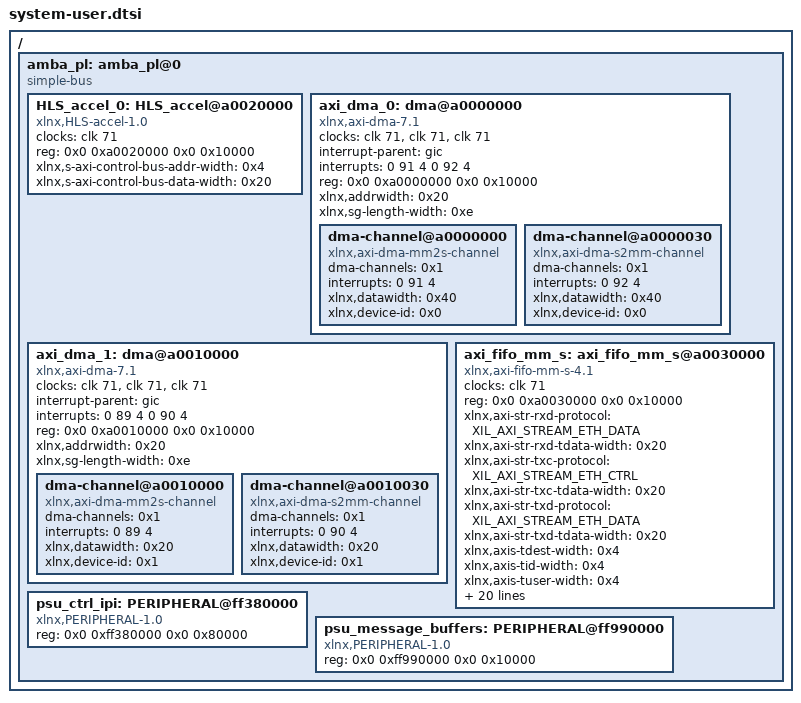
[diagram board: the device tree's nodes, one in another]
/include/ "system-conf.dtsi"
/ {
};
/ {
	amba_pl: amba_pl@0 {
		#address-cells = <2>;
		#size-cells = <2>;
		compatible = "simple-bus";
		ranges ;
		HLS_accel_0: HLS_accel@a0020000 {
			clock-names = "ap_clk";
			clocks = <&clk 71>;
			compatible = "xlnx,HLS-accel-1.0";
			reg = <0x0 0xa0020000 0x0 0x10000>;
			xlnx,s-axi-control-bus-addr-width = <0x4>;
			xlnx,s-axi-control-bus-data-width = <0x20>;
		};
		axi_dma_0: dma@a0000000 {
			#dma-cells = <1>;
			clock-names = "s_axi_lite_aclk", "m_axi_mm2s_aclk", "m_axi_s2mm_aclk";
			clocks = <&clk 71>, <&clk 71>, <&clk 71>;
			compatible = "xlnx,axi-dma-7.1", "xlnx,axi-dma-1.00.a", "generic-uio";
			interrupt-names = "mm2s_introut", "s2mm_introut";
			interrupt-parent = <&gic>;
			interrupts = <0 91 4 0 92 4>;
			reg = <0x0 0xa0000000 0x0 0x10000>;
			xlnx,addrwidth = <0x20>;
			xlnx,sg-length-width = <0xe>;
			dma-channel@a0000000 {
				compatible = "xlnx,axi-dma-mm2s-channel";
				dma-channels = <0x1>;
				interrupts = <0 91 4>;
				xlnx,datawidth = <0x40>;
				xlnx,device-id = <0x0>;
			};
			dma-channel@a0000030 {
				compatible = "xlnx,axi-dma-s2mm-channel";
				dma-channels = <0x1>;
				interrupts = <0 92 4>;
				xlnx,datawidth = <0x40>;
				xlnx,device-id = <0x0>;
			};
		};
		axi_dma_1: dma@a0010000 {
			#dma-cells = <1>;
			clock-names = "s_axi_lite_aclk", "m_axi_mm2s_aclk", "m_axi_s2mm_aclk";
			clocks = <&clk 71>, <&clk 71>, <&clk 71>;
			compatible = "xlnx,axi-dma-7.1", "xlnx,axi-dma-1.00.a", "generic-uio";
			interrupt-names = "mm2s_introut", "s2mm_introut";
			interrupt-parent = <&gic>;
			interrupts = <0 89 4 0 90 4>;
			reg = <0x0 0xa0010000 0x0 0x10000>;
			xlnx,addrwidth = <0x20>;
			xlnx,sg-length-width = <0xe>;
			dma-channel@a0010000 {
				compatible = "xlnx,axi-dma-mm2s-channel";
				dma-channels = <0x1>;
				interrupts = <0 89 4>;
				xlnx,datawidth = <0x20>;
				xlnx,device-id = <0x1>;
			};
			dma-channel@a0010030 {
				compatible = "xlnx,axi-dma-s2mm-channel";
				dma-channels = <0x1>;
				interrupts = <0 90 4>;
				xlnx,datawidth = <0x20>;
				xlnx,device-id = <0x1>;
			};
		};
		axi_fifo_mm_s: axi_fifo_mm_s@a0030000 {
			clock-names = "s_axi_aclk";
			clocks = <&clk 71>;
			compatible = "xlnx,axi-fifo-mm-s-4.1";
			reg = <0x0 0xa0030000 0x0 0x10000>;
			xlnx,axi-str-rxd-protocol = "XIL_AXI_STREAM_ETH_DATA";
			xlnx,axi-str-rxd-tdata-width = <0x20>;
			xlnx,axi-str-txc-protocol = "XIL_AXI_STREAM_ETH_CTRL";
			xlnx,axi-str-txc-tdata-width = <0x20>;
			xlnx,axi-str-txd-protocol = "XIL_AXI_STREAM_ETH_DATA";
			xlnx,axi-str-txd-tdata-width = <0x20>;
			xlnx,axis-tdest-width = <0x4>;
			xlnx,axis-tid-width = <0x4>;
			xlnx,axis-tuser-width = <0x4>;
			xlnx,data-interface-type = <0x0>;
			xlnx,has-axis-tdest = <0x0>;
			xlnx,has-axis-tid = <0x0>;
			xlnx,has-axis-tkeep = <0x0>;
			xlnx,has-axis-tstrb = <0x0>;
			xlnx,has-axis-tuser = <0x0>;
			xlnx,rx-fifo-depth = <0x200>;
			xlnx,rx-fifo-pe-threshold = <0x2>;
			xlnx,rx-fifo-pf-threshold = <0x1fb>;
			xlnx,s-axi-id-width = <0x4>;
			xlnx,s-axi4-data-width = <0x20>;
			xlnx,select-xpm = <0x0>;
			xlnx,tx-fifo-depth = <0x200>;
			xlnx,tx-fifo-pe-threshold = <0x2>;
			xlnx,tx-fifo-pf-threshold = <0x1fb>;
			xlnx,use-rx-cut-through = <0x0>;
			xlnx,use-rx-data = <0x0>;
			xlnx,use-tx-ctrl = <0x1>;
			xlnx,use-tx-cut-through = <0x0>;
			xlnx,use-tx-data = <0x1>;
		};
		psu_ctrl_ipi: PERIPHERAL@ff380000 {
			compatible = "xlnx,PERIPHERAL-1.0";
			reg = <0x0 0xff380000 0x0 0x80000>;
		};
		psu_message_buffers: PERIPHERAL@ff990000 {
			compatible = "xlnx,PERIPHERAL-1.0";
			reg = <0x0 0xff990000 0x0 0x10000>;
		};
	};
};
